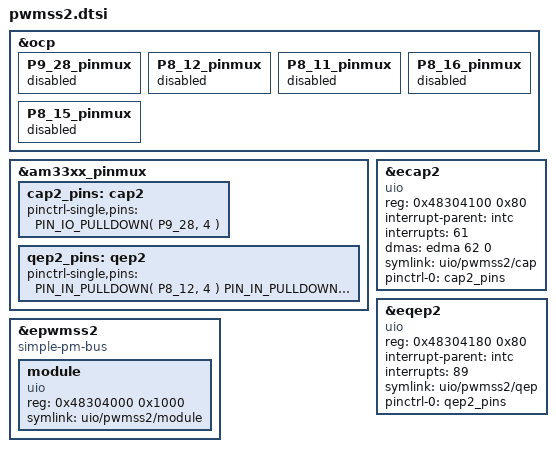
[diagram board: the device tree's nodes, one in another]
#include "subarctic/pinctrl.h"
#include "bone/pins.h"

// disable cape-universal pinmux helper nodes for pins used by this overlay
&ocp {
	P9_28_pinmux {  status = "disabled";  };  // cap 2
	P8_12_pinmux {  status = "disabled";  };  // qep 2 A
	P8_11_pinmux {  status = "disabled";  };  // qep 2 B
	P8_16_pinmux {  status = "disabled";  };  // qep 2 index
	P8_15_pinmux {  status = "disabled";  };  // qep 2 strobe
#if 0
	P8_19_pinmux {  status = "disabled";  };  // pwm 2 A
	P8_13_pinmux {  status = "disabled";  };  // pwm 2 B
	P8_14_pinmux {  status = "disabled";  };  // pwm tripzone 2
#endif
};

&am33xx_pinmux {
	cap2_pins: cap2 {
		pinctrl-single,pins = <
			PIN_IO_PULLDOWN( P9_28, 4 )  // cap 2
		>;
	};

	qep2_pins: qep2 {
		pinctrl-single,pins = <
			PIN_IN_PULLDOWN( P8_12, 4 )  // qep 2 A
			PIN_IN_PULLDOWN( P8_11, 4 )  // qep 2 B
			PIN_IO_PULLDOWN( P8_16, 4 )  // qep 2 index
			PIN_IO_PULLDOWN( P8_15, 4 )  // qep 2 strobe
		>;
	};

#if 0
	pwm2_pins: pwm2 {
		pinctrl-single,pins = <
			PIN_OUT_PULLDOWN( P8_19, 4 )  // pwm 2 A
			PIN_OUT_PULLDOWN( P8_13, 4 )  // pwm 2 B
		>;
	};

	pwm2_tz_pins: pwm2-tz {
		pinctrl-single,pins = <
			PIN_IN_PULLDOWN( P8_14, 4 )  // pwm tripzone 2
		>;
	};
#endif
};

&epwmss2 {
	status = "okay";
	compatible = "simple-pm-bus", "ti,am33xx-pwmss";
	ranges = <0x48304000 0x48304000 0x1000>;

	// The individual submodules are smaller than a page (in fact the
	// pwmss subsystem occupies only a single 4K page), so make an uio
	// device for the whole address range.
	module {
		reg = <0x48304000 0x1000>;
		compatible = "uio";
		symlink = "uio/pwmss2/module";
	};

	// see below for child nodes &ecap2, &eqep2, &ehrpwm2

#if 0
	// add device for pwm tripzone irq
	pwm-tz {
		interrupt-parent = <&intc>;
		interrupts = <60>;
		compatible = "uio";
		symlink = "uio/pwmss2/pwm-tz";

		pinctrl-names = "default";
		pinctrl-0 = <&pwm2_tz_pins>;
	};
#endif
};

&ecap2 {
	reg = <0x48304100 0x80>;

	interrupt-parent = <&intc>;
	interrupts = <61>;

	dmas = <&edma 62 0>;

	compatible = "uio";
	symlink = "uio/pwmss2/cap";
	status = "okay";

	pinctrl-names = "default";
	pinctrl-0 = <&cap2_pins>;
};

&eqep2 {
	reg = <0x48304180 0x80>;

	interrupt-parent = <&intc>;
	interrupts = <89>;

	compatible = "uio";
	symlink = "uio/pwmss2/qep";
	status = "okay";

	pinctrl-names = "default";
	pinctrl-0 = <&qep2_pins>;
};

#if 0
&ehrpwm2 {
	reg = <0x48304200 0x80>, <0x48304280 0x80>;
	reg-names = "pwm", "hr";

	interrupt-parent = <&intc>;
	interrupts = <39>, <60>;
	interrupt-names = "pwm", "tz";

	dmas = <&edma 63 0>;

	compatible = "uio";
	symlink = "uio/pwmss2/pwm";
	status = "okay";

	pinctrl-names = "default";
	pinctrl-0 = <&pwm2_pins>;
};
#endif
